# V32F20x_CM33 register map
File version: 1.0.3
CPU: CM33 r0p4, little endian, MPU, FPU, DSP, 3 interrupt priority bits, 8 SAU regions
Registers are 32-bit, read-write, reset 0x0 unless marked. A register's access mark holds for its fields unless they carry their own. Offsets are from the block's base; [hi:lo] are bit positions; {n}, {i} and the like mark numbered series.

## OSPI0 — OSPI0 Peripheral Interface
Base 0x60000000
Same registers: OSPI1 0x64000000, SEC_OSPI0 0x70000000, SEC_OSPI1 0x74000000
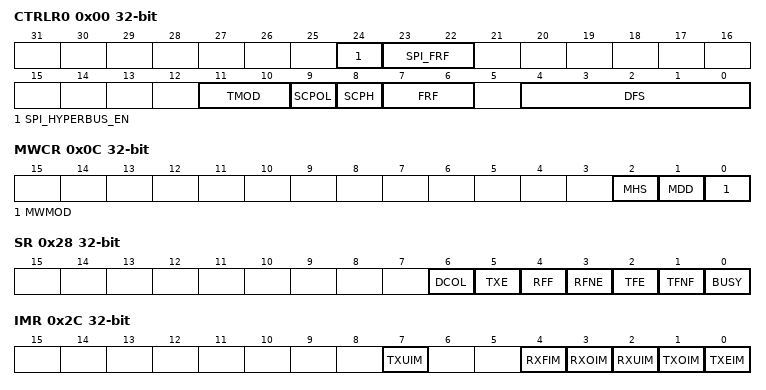
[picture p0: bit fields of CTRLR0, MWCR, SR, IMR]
0x00 CTRLR0 — Control Register 0.
  [24] SPI_HYPERBUS_EN — SPI Hyperbus Frame format enable
  [23:22] SPI_FRF — SPI Frame Format
  [11:10] TMOD — Transfer Mode
  [9] SCPOL — Serial Clock Polarity
  [8] SCPH — Serial Clock Phase
  [7:6] FRF — Frame Format
  [4:0] DFS — Data Frame Size in 32-bit transfer size mode
0x04 CTRLR1 — Control Register 1.
  [15:0] NDF — Number of Data Frames
0x08 OSPIEN — OSPI Enable Register.
  [0] OSPI_EN — OSPI Enable
0x0C MWCR — Microwire Control Register.
  [2] MHS — Microwire Handshaking
  [1] MDD — Microwire Control
  [0] MWMOD — Microwire Transfer Mode
0x10 SER — Slave Enable Register.
  [3:0] SER — Slave Select Enable Flag
0x14 BAUDR — Baud Rate Select.
  [15:1] SCKDV — OSPI Clock Divider
0x18 TXFTLR — Transmit FIFO Threshold Level.
  [4:0] TFT — Transmit FIFO Threshold
0x1C RXFTLR — Receive FIFO Threshold Level.
  [4:0] RFT — Receive FIFO Threshold
0x20 TXFLR ro — Transmit FIFO Level Register.
  [4:0] TXTFL — Transmit FIFO Level
0x24 RXFLR ro — Receive FIFO Level Register.
  [4:0] RXTFL — Receive FIFO Level
0x28 SR ro — Status Register.
  [6] DCOL — Data Collision Error
  [5] TXE — Transmission Error
  [4] RFF — Receive FIFO Full
  [3] RFNE — Receive FIFO Not Empty
  [2] TFE — Transmit FIFO Empty
  [1] TFNF — Transmit FIFO Not Full
  [0] BUSY — OSPI Busy Flag
0x2C IMR — Interrupt Mask Register.
  [7] TXUIM — Transmit FIFO Underflow Interrupt Mask
  [4] RXFIM — Receive FIFO Full Interrupt Mask
  [3] RXOIM — Receive FIFO Overflow Interrupt Mask
  [2] RXUIM — Receive FIFO Underflow Interrupt Mask
  [1] TXOIM — Transmit FIFO Overflow Interrupt Mask
  [0] TXEIM — Transmit FIFO Empty Interrupt Mask
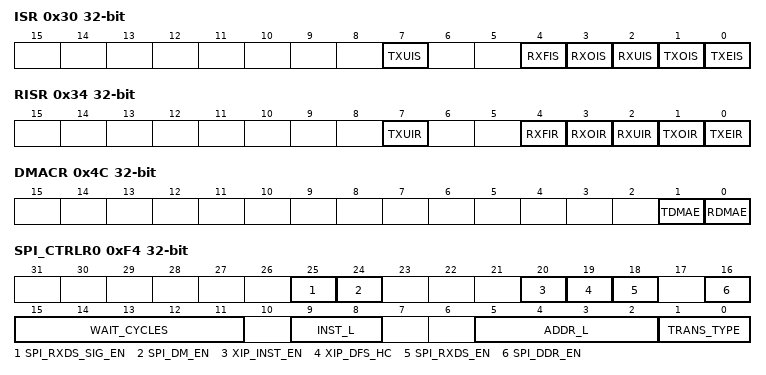
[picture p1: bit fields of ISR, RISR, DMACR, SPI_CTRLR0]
0x30 ISR ro — Interrupt Status Register.
  [7] TXUIS — Transmit FIFO Underflow Interrupt Status
  [4] RXFIS — Receive FIFO Full Interrupt Status
  [3] RXOIS — Receive FIFO Overflow Interrupt Status
  [2] RXUIS — Receive FIFO Underflow Interrupt Status
  [1] TXOIS — Transmit FIFO Overflow Interrupt Status
  [0] TXEIS — Transmit FIFO Empty Interrupt Status
0x34 RISR ro — Raw Interrupt Status Register.
  [7] TXUIR — Transmit FIFO Underflow Raw Interrupt Status
  [4] RXFIR — Receive FIFO Full Raw Interrupt Status
  [3] RXOIR — Receive FIFO Overflow Raw Interrupt Status
  [2] RXUIR — Receive FIFO Underflow Raw Interrupt Status
  [1] TXOIR — Transmit FIFO Overflow Raw Interrupt Status
  [0] TXEIR — Transmit FIFO Empty Raw Interrupt Status
0x38 TXEICR ro — Transmit FIFO Error Interrupt Clear Registers.
  [0] TXEICR — Clear Transmit FIFO Overflow/Underflow Interrupt
0x3C RXOICR ro — Receive FIFO Overflow Interrupt Clear Register.
  [0] RXOICR — Clear Receive FIFO Overflow Interrupt
0x40 RXUICR ro — Receive FIFO Underflow Interrupt Clear Register.
  [0] RXUICR — Clear Receive FIFO Underflow Interrupt
0x48 ICR ro — Interrupt Clear Register.
  [0] ICR — Clear Interrupts
0x4C DMACR — DMA Control Register.
  [1] TDMAE — Transmit DMA Enable
  [0] RDMAE — Receive DMA Enable
0x50 DMATDLR — DMA Transmit Data Level.
  [4:0] DMATDL — Transmit Data Level
0x54 DMARDLR — DMA Receive Data Level.
  [4:0] DMARDL — Receive Data Level
{0x60+4i} DR{i} (i=0..35) — OSPI Data Register.
  [31:0] DR — Data Register
0xF4 SPI_CTRLR0 — SPI Control Register.
  [25] SPI_RXDS_SIG_EN — Enable rxds signaling during address and command phase of Hypebus transfer
  [24] SPI_DM_EN — SPI data mask enable bit
  [20] XIP_INST_EN — XIP instruction enable bit
  [19] XIP_DFS_HC — Fix DFS for XIP transfers
  [18] SPI_RXDS_EN — Read data strobe enable bit
  [16] SPI_DDR_EN — SPI DDR Enable bit
  [15:11] WAIT_CYCLES — Wait cycles in Dual Quad Octal mode between control frames transmit and data reception
  [9:8] INST_L — Dual/Quad/Octal mode instruction length in bits.
  [5:2] ADDR_L — This bit defines Length of Address to be transmitted
  [1:0] TRANS_TYPE — Address and instruction transfer format.
0xF8 DDR_DRIVE_EDGE — Transmit Drive Edge Register.
  [7:0] TDE — TXD Drive edge register which decided the driving edge of transmit data
0x100 XIP_INCR_INST — XIP INCR transfer opcode.
  [15:0] INCR_INST
0x104 XIP_WRAP_INST — XIP WRAP transfer opcode.
  [15:0] WRAP_INST
0x140 XIP_WRITE_INCR_INST — XIP Write INCR transfer opcode
  [15:0] INCR_WRINST — XIP Write INCR transfer opcode.
0x144 XIP_WRITE_WRAP_INST — XIP Write WRAP transfer opcode
  [15:0] WRAP_WRINST — XIP Write WRAP transfer opcode.
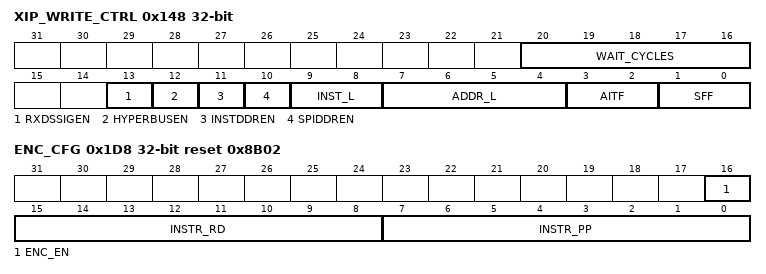
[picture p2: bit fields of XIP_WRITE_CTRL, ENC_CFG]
0x148 XIP_WRITE_CTRL — XIP Write Control Register
  [20:16] WAIT_CYCLES — Wait cycles in Dual Quad Octal mode between control frames transmit and data reception
  [13] RXDSSIGEN — Enable rxds signaling during address and command phase of Hyperbus transfer
  [12] HYPERBUSEN — SPI Hyperbus Frame format enable for XIP Write transfers
  [11] INSTDDREN — Instruction DDR Enable bit.
  [10] SPIDDREN — SPI DDR Enable bit.
  [9:8] INST_L — Dual/Quad/Octal mode instruction length in bits.
  [7:4] ADDR_L — This bit defines Length of Address to be transmitted
  [3:2] AITF — Address and instruction transfer format.
  [1:0] SFF — SPI Frame Format.
{0x1C0+4i} KEY{i} (i=0..2) — OSPI decryption key register {i}
  [31:0] KEY_{i} — The bit {32i+31} {32i} of the 128 bit KEY used for OSPI decryption
0x1CC KEY3 — OSPI decryption key register 3
  [31:0] KEY_3 — The bit 127 96 of of the 128 bit KEY used for OSPI decryption function
0x1D0 IV0 — OSPI decryption initial vector register 0
  [31:0] IV_0 — The bit 31 0 of initial vector used for OSPI decryption function
0x1D4 IV1 — OSPI decryption initial vector register 1
  [31:0] IV_1 — The bit 63 32 of initial vector used for OSPI decryption function
0x1D8 ENC_CFG reset 0x8B02 — OSPI decryption configuration register
  [16] ENC_EN — Encryption and decryption enable bit.
  [15:8] INSTR_RD — The instruction of Read
  [7:0] INSTR_PP — The command value of Page Program
